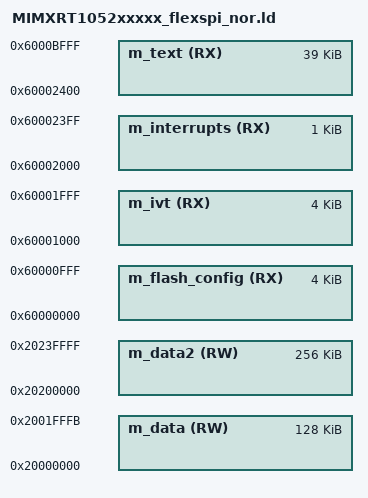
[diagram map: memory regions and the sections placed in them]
/*
** ###################################################################
**     Processors:          MIMXRT1052CVJ5B
**                          MIMXRT1052CVL5B
**                          MIMXRT1052DVJ6B
**                          MIMXRT1052DVL6B
**
**     Compiler:            GNU C Compiler
**     Reference manual:    IMXRT1050RM Rev.1, 03/2018
**     Version:             rev. 1.0, 2018-09-21
**     Build:               b180921
**
**     Abstract:
**         Linker file for the GNU C Compiler
**
**     Copyright 2016 Freescale Semiconductor, Inc.
**     Copyright 2016-2018 NXP
**     All rights reserved.
**
**     SPDX-License-Identifier: BSD-3-Clause
**
**     http:                 www.nxp.com
**     mail:                 support@nxp.com
**
** ###################################################################
*/

/* Specify the memory areas */
MEMORY
{
  m_flash_config        (RX)  : ORIGIN = 0x60000000, LENGTH = 0x00001000
  m_ivt                 (RX)  : ORIGIN = 0x60001000, LENGTH = 0x00001000
  m_interrupts          (RX)  : ORIGIN = 0x60002000, LENGTH = 0x00000400
  m_text                (RX)  : ORIGIN = 0x60002400, LENGTH = 0x6000C000-0x60002400
  m_data                (RW)  : ORIGIN = 0x20000000, LENGTH = 0x00020000 - 4 /* double tap */
  m_data2               (RW)  : ORIGIN = 0x20200000, LENGTH = 0x00040000
}

INCLUDE "rt10xx_common.ld"
